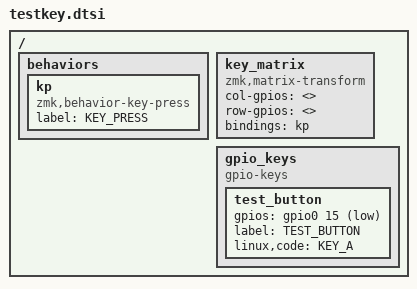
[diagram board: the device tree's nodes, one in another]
/ {
    // 单按钮测试板
    behaviors {
        kp: kp {
            compatible = "zmk,behavior-key-press";
            label = "KEY_PRESS";
        };
    };

    key_matrix {
        compatible = "zmk,matrix-transform";
        col-gpios = <>;
        row-gpios = <>;
        bindings = <&kp>;
    };

    gpio_keys {
        compatible = "gpio-keys";
        test_button: test_button {
            gpios = <&gpio0 15 (GPIO_ACTIVE_LOW | GPIO_PULL_UP)>; // P0.15
            label = "TEST_BUTTON";
            linux,code = <KEY_A>;
        };
    };
};
